AUTOSAR XML (schema 4-2-2)
package /AUTOLIV/SoftwareComponents/eCS
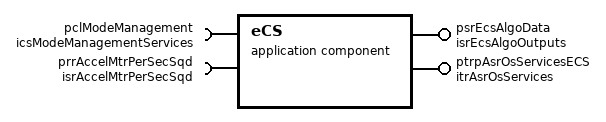
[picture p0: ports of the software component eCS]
  application sw component type eCS: category=SWC  # eCS_AC_ElectricalCarSensor
    require port pclModeManagement: client-com-spec=CheckModeStatus, required-interface=icsModeManagementServices
    require port prrAccelMtrPerSecSqd: nonqueued-receiver-com-spec{data-element=stAccelMtrPerSecSqd, enable-update=true, init-value=fields=[0, 0, 0]}, required-interface=isrAccelMtrPerSecSqd  # # Architecture Element ID ARCH_SW_eCS_prrAccelMtrPerSecSqd # Description - The runnable shall read the acceleration on X,Y,Z axis in m/s^2 # Data Flow ## Inputs ## Outputs - {Acceleration X} - {Acceleration Y} - {Acceleration Z} #Linked Runnable - eCS_runMainFunction # Traceability
    provide port psrEcsAlgoData: provided-interface=isrEcsAlgoOutputs  # # Architecture Element ID ARCH_SW_eCS_psrEcsAlgoData_u8EcsFlag # Description - The runnable shall write the {Ball Algorithm Status} output parameter - The runnable shall compute the status of the ball algorithm based on the acceleration on X,Y,Z axis - The runnable shall force the algorithm output to either LOCK or UNLOCK if a request for testing the actuator was received via the diagnostic request interface # Data Flow ## Inputs - {Acceleration on X} - {Acceleration on Y} - {Acceleration on Z} ## Outputs - {Ball Algorithm Status} - Can be LOCKED,UNLOCKED #Linked Runnable - eCS_runMainFunction # Traceability ----------------------------------------------------------------------------------------- # Architecture Element ID ARCH_SW_eCS_psrEcsAlgoData_u16BallPosition # Description - The runnable shall compute the position of the virtual ball based on the acceleration on X,Y,Z axis in mm # Data Flow ## Inputs - {Acceleration on X} - {Acceleration on Y} - {Acceleration on Z} ## Outputs - {Virtual Ball Position} #Linked Runnable - eCS_runMainFunction # Traceability
      provided-com-specs:
        data-element=u8EcsFlag, uses-end-to-end-protection=0, init-value=KU8_ECS_ALGO_LOCK
        data-element=u16BallPosition, uses-end-to-end-protection=0, init-value=0
    provide port ptrpAsrOsServicesECS: provided-interface=itrAsrOsServices  # # Architecture Element ID ARCH_SW_eCS_ptrpAsrOsServices # Description - The runnable shall be called each 1mS by the Autosar OS - The runnable will execute the algo after the INIT phase will be finished; - If the time between two consecutives LOCK request is below NVP_u16DelayBetweenUnlocks, the delay time before performing a new UNLOCK should be forece to NVP_u16LatchTmrLong * 0.5 ms. - If the time between two consecutives LOCK request is above or equal to NVP_u16DelayBetweenUnlocks, the delay time before performing a new UNLOCK should be forece to NVP_u16LatchTmr * 0.5 ms. # Data Flow ## Inputs ## Outputs #Linked Runnable - eCS_runMainFunction # Traceability DOM_eCS_TF_R_69; DOM_eCS_TF_R_185; DOM_eCS_TF_R_66; DOM_eCS_TF_R_67; DOM_eCS_TF_R_29; DOM_eCS_TF_R_32; DOM_eCS_TF_R_33;
